# HDSC_HC32F480 register map
Vendor: HDSC Co.Ltd; Series: ARMCM4; File version: 1.2
CPU: CM0 r0p0, little endian, no MPU, no FPU, 3 interrupt priority bits
Registers are 16-bit, read-write, reset 0x0 unless marked. A register's access mark holds for its fields unless they carry their own. Offsets are from the block's base; [hi:lo] are bit positions; {n}, {i} and the like mark numbered series; 'fields as' and 'values as' point back to an identical list.

## PORT
Base 0x40053800
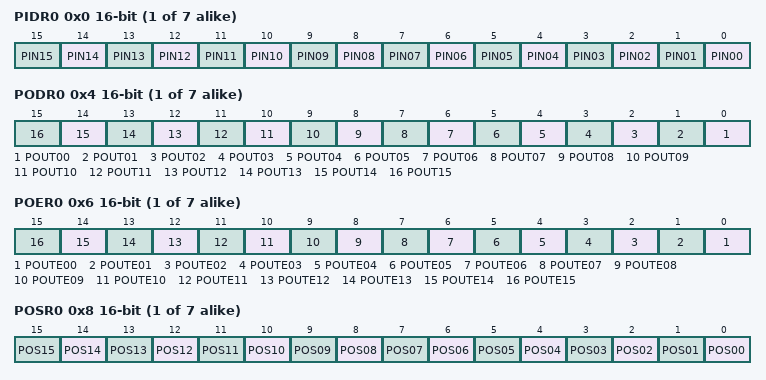
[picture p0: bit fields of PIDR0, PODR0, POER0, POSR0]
{0x0+0x10*i} PIDR{i} ro (i=0..6)
  [n] PIN{n:02} (n=0..15)
{0x4+0x10*i} PODR{i} (i=0..6)
  [n] POUT{n:02} (n=0..15)
{0x6+0x10*i} POER{i} (i=0..6)
  [n] POUTE{n:02} (n=0..15)
{0x8+0x10*i} POSR{i} wo (i=0..6)
  [n] POS{n:02} (n=0..15)
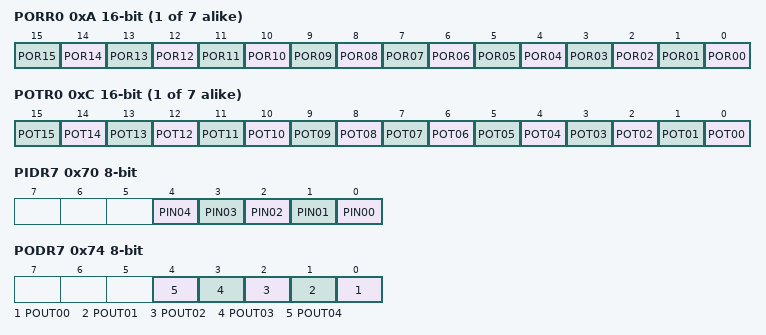
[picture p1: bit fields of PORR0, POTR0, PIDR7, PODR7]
{0xA+0x10*i} PORR{i} wo (i=0..6)
  [n] POR{n:02} (n=0..15)
{0xC+0x10*i} POTR{i} wo (i=0..6)
  [n] POT{n:02} (n=0..15)
0x70 PIDR7 8-bit ro
  [n] PIN{n:02} (n=0..4)
0x74 PODR7 8-bit
  [n] POUT{n:02} (n=0..4)
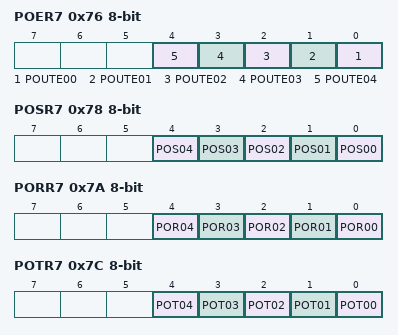
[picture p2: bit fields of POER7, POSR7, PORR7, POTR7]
0x76 POER7 8-bit
  [n] POUTE{n:02} (n=0..4)
0x78 POSR7 8-bit wo
  [n] POS{n:02} (n=0..4)
0x7A PORR7 8-bit wo
  [n] POR{n:02} (n=0..4)
0x7C POTR7 8-bit wo
  [n] POT{n:02} (n=0..4)
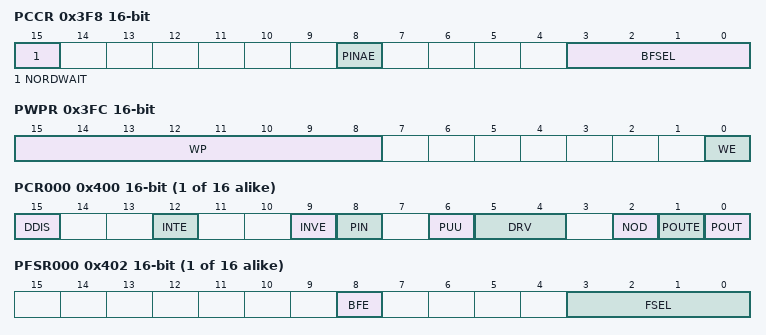
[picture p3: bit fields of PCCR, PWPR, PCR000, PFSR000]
0x3F8 PCCR
  [15] NORDWAIT, [8] PINAE, [3:0] BFSEL
0x3FC PWPR
  [15:8] WP wo, [0] WE
{0x400+4i} PCR{i:03} (i=0..15)
  [15] DDIS, [12] INTE, [9] INVE, [8] PIN ro, [6] PUU, [5:4] DRV, [2] NOD, [1] POUTE, [0] POUT
{0x402+4i} PFSR{i:03} (i=0..15)
  [8] BFE, [3:0] FSEL
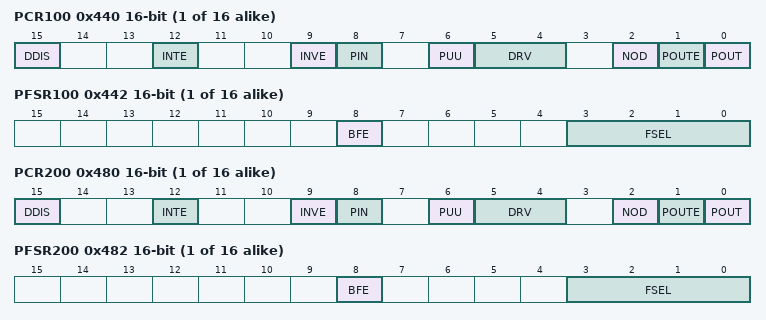
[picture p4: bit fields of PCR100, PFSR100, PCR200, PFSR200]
{0x2B0+4i} PCR{i} (i=100..115)
  fields as PCR000
{0x2B2+4i} PFSR{i} (i=100..115)
  [8] BFE, [3:0] FSEL
{0x160+4i} PCR{i} (i=200..215)
  fields as PCR000
{0x162+4i} PFSR{i} (i=200..215)
  [8] BFE, [3:0] FSEL
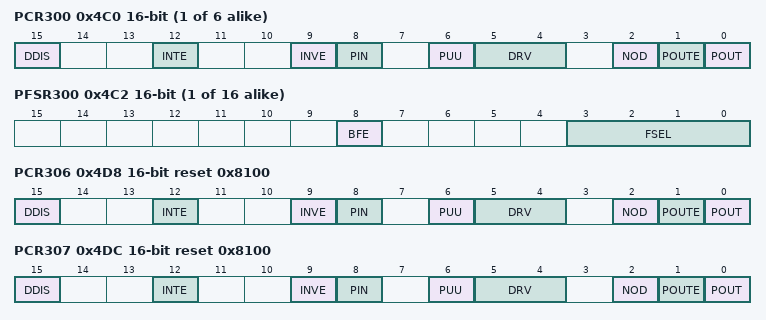
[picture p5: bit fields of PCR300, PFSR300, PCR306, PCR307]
{0x10+4i} PCR{i} (i=300..305)
  fields as PCR000
{0x12+4i} PFSR{i} (i=300..315)
  [8] BFE, [3:0] FSEL
0x4D8 PCR306 reset 0x8100
  fields as PCR000
0x4DC PCR307 reset 0x8100
  fields as PCR000
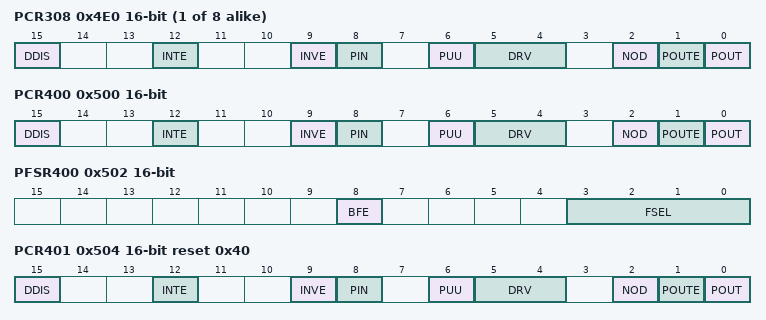
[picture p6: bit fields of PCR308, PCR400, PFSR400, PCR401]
{0x10+4i} PCR{i} (i=308..315)
  fields as PCR000
0x500 PCR400
  fields as PCR000
0x502 PFSR400
  [8] BFE, [3:0] FSEL
0x504 PCR401 reset 0x40
  fields as PCR000
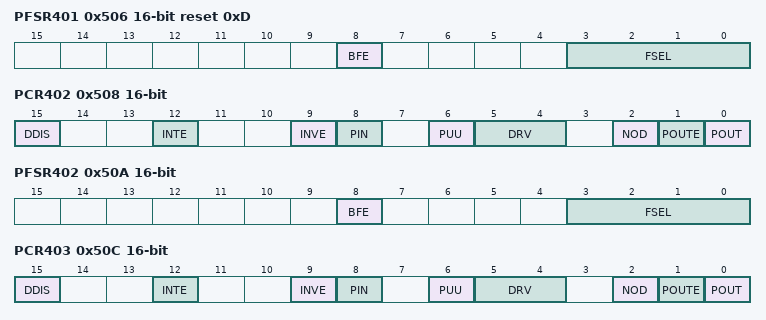
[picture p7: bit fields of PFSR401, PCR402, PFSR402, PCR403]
0x506 PFSR401 reset 0xD
  [8] BFE, [3:0] FSEL
0x508 PCR402
  fields as PCR000
0x50A PFSR402
  [8] BFE, [3:0] FSEL
0x50C PCR403
  fields as PCR000
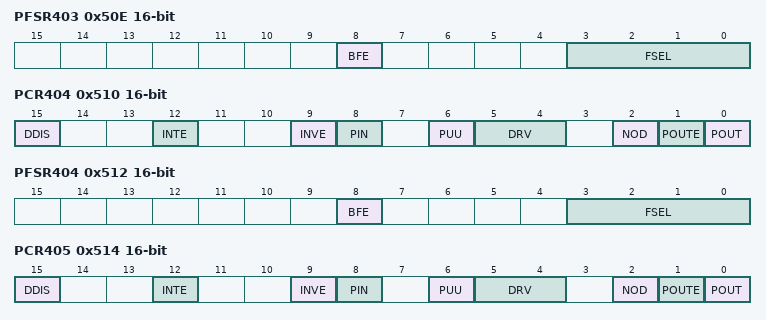
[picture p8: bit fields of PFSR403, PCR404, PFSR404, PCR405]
0x50E PFSR403
  [8] BFE, [3:0] FSEL
0x510 PCR404
  fields as PCR000
0x512 PFSR404
  [8] BFE, [3:0] FSEL
0x514 PCR405
  fields as PCR000
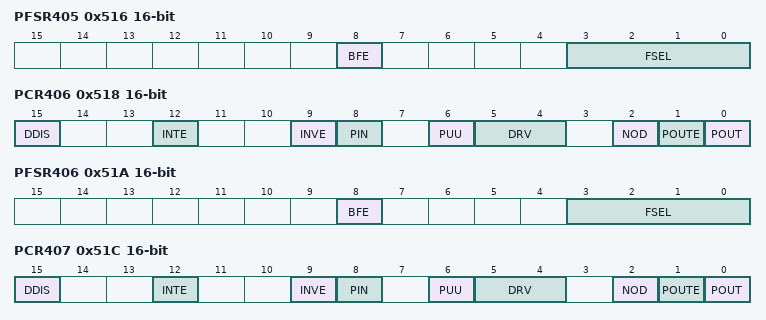
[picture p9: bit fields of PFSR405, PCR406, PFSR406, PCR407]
0x516 PFSR405
  [8] BFE, [3:0] FSEL
0x518 PCR406
  fields as PCR000
0x51A PFSR406
  [8] BFE, [3:0] FSEL
0x51C PCR407
  fields as PCR000
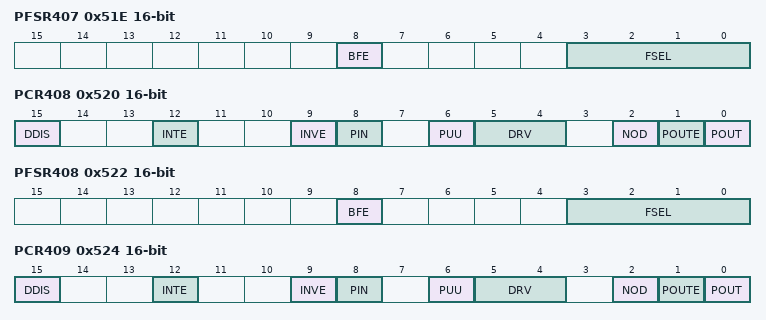
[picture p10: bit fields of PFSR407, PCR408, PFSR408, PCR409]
0x51E PFSR407
  [8] BFE, [3:0] FSEL
0x520 PCR408
  fields as PCR000
0x522 PFSR408
  [8] BFE, [3:0] FSEL
0x524 PCR409
  fields as PCR000
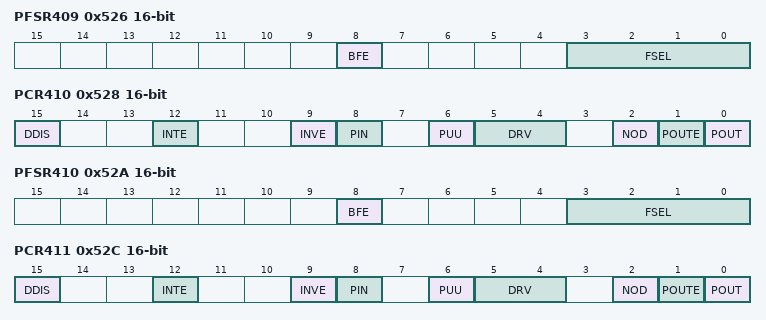
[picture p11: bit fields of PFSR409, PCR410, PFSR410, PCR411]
0x526 PFSR409
  [8] BFE, [3:0] FSEL
0x528 PCR410
  fields as PCR000
0x52A PFSR410
  [8] BFE, [3:0] FSEL
0x52C PCR411
  fields as PCR000
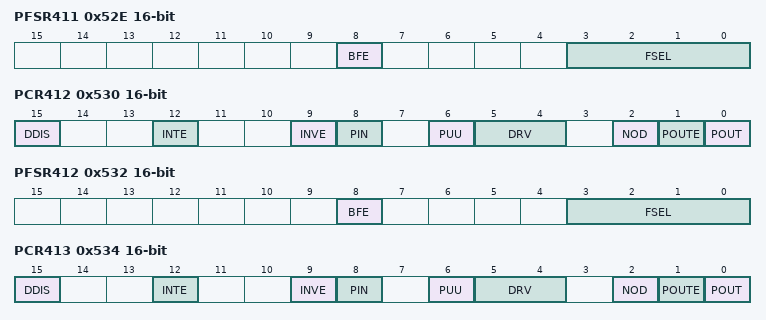
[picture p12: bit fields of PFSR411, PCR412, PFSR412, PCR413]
0x52E PFSR411
  [8] BFE, [3:0] FSEL
0x530 PCR412
  fields as PCR000
0x532 PFSR412
  [8] BFE, [3:0] FSEL
0x534 PCR413
  fields as PCR000
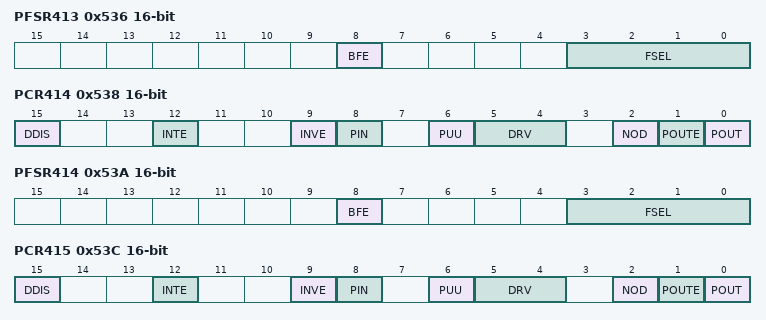
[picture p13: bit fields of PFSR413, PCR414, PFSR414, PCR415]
0x536 PFSR413
  [8] BFE, [3:0] FSEL
0x538 PCR414
  fields as PCR000
0x53A PFSR414
  [8] BFE, [3:0] FSEL
0x53C PCR415
  fields as PCR000
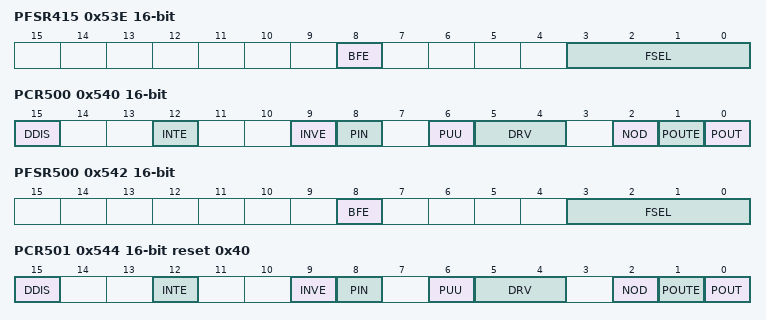
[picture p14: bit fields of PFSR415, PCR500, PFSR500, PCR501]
0x53E PFSR415
  [8] BFE, [3:0] FSEL
0x540 PCR500
  fields as PCR000
0x542 PFSR500
  [8] BFE, [3:0] FSEL
0x544 PCR501 reset 0x40
  fields as PCR000
0x546 PFSR501 reset 0xD
  [8] BFE, [3:0] FSEL
0x548 PCR502 reset 0x50
  fields as PCR000
0x54A PFSR502 reset 0xD
  [8] BFE, [3:0] FSEL
0x54C PCR503 reset 0x10
  fields as PCR000
0x54E PFSR503 reset 0xD
  [8] BFE, [3:0] FSEL
0x550 PCR504 reset 0x40
  fields as PCR000
0x552 PFSR504 reset 0xD
  [8] BFE, [3:0] FSEL
0x554 PCR505
  fields as PCR000
0x556 PFSR505
  [8] BFE, [3:0] FSEL
0x558 PCR506
  fields as PCR000
0x55A PFSR506
  [8] BFE, [3:0] FSEL
0x55C PCR507
  fields as PCR000
0x55E PFSR507
  [8] BFE, [3:0] FSEL
0x560 PCR508
  fields as PCR000
0x562 PFSR508
  [8] BFE, [3:0] FSEL
0x564 PCR509
  fields as PCR000
0x566 PFSR509
  [8] BFE, [3:0] FSEL
0x568 PCR510
  fields as PCR000
0x56A PFSR510
  [8] BFE, [3:0] FSEL
0x56C PCR511
  fields as PCR000
0x56E PFSR511
  [8] BFE, [3:0] FSEL
0x570 PCR512
  fields as PCR000
0x572 PFSR512
  [8] BFE, [3:0] FSEL
0x574 PCR513
  fields as PCR000
0x576 PFSR513
  [8] BFE, [3:0] FSEL
0x578 PCR514
  fields as PCR000
0x57A PFSR514
  [8] BFE, [3:0] FSEL
0x57C PCR515
  fields as PCR000
0x57E PFSR515
  [8] BFE, [3:0] FSEL
0x580 PCR600
  fields as PCR000
0x582 PFSR600
  [8] BFE, [3:0] FSEL
0x584 PCR601
  fields as PCR000
0x586 PFSR601
  [8] BFE, [3:0] FSEL
0x588 PCR602
  fields as PCR000
0x58A PFSR602
  [8] BFE, [3:0] FSEL
0x58C PCR603
  fields as PCR000
0x58E PFSR603
  [8] BFE, [3:0] FSEL
0x590 PCR604
  fields as PCR000
0x592 PFSR604
  [8] BFE, [3:0] FSEL
0x594 PCR605
  fields as PCR000
0x596 PFSR605
  [8] BFE, [3:0] FSEL
0x598 PCR606
  fields as PCR000
0x59A PFSR606
  [8] BFE, [3:0] FSEL
0x59C PCR607
  fields as PCR000
0x59E PFSR607
  [8] BFE, [3:0] FSEL
0x5A0 PCR608
  fields as PCR000
0x5A2 PFSR608
  [8] BFE, [3:0] FSEL
0x5A4 PCR609
  fields as PCR000
0x5A6 PFSR609
  [8] BFE, [3:0] FSEL
0x5A8 PCR610
  fields as PCR000
0x5AA PFSR610
  [8] BFE, [3:0] FSEL
0x5AC PCR611
  fields as PCR000
0x5AE PFSR611
  [8] BFE, [3:0] FSEL
0x5B0 PCR612
  fields as PCR000
0x5B2 PFSR612
  [8] BFE, [3:0] FSEL
0x5B4 PCR613
  fields as PCR000
0x5B6 PFSR613
  [8] BFE, [3:0] FSEL
0x5B8 PCR614
  fields as PCR000
0x5BA PFSR614
  [8] BFE, [3:0] FSEL
0x5BC PCR615
  fields as PCR000
0x5BE PFSR615
  [8] BFE, [3:0] FSEL
0x5C0 PCR700
  fields as PCR000
0x5C2 PFSR700
  [8] BFE, [3:0] FSEL
0x5C4 PCR701
  fields as PCR000
0x5C6 PFSR701
  [8] BFE, [3:0] FSEL
0x5C8 PCR702
  fields as PCR000
0x5CA PFSR702
  [8] BFE, [3:0] FSEL
0x5CC PCR703
  fields as PCR000
0x5CE PFSR703
  [8] BFE, [3:0] FSEL
0x5D0 PCR704
  fields as PCR000
0x5D2 PFSR704
  [8] BFE, [3:0] FSEL
